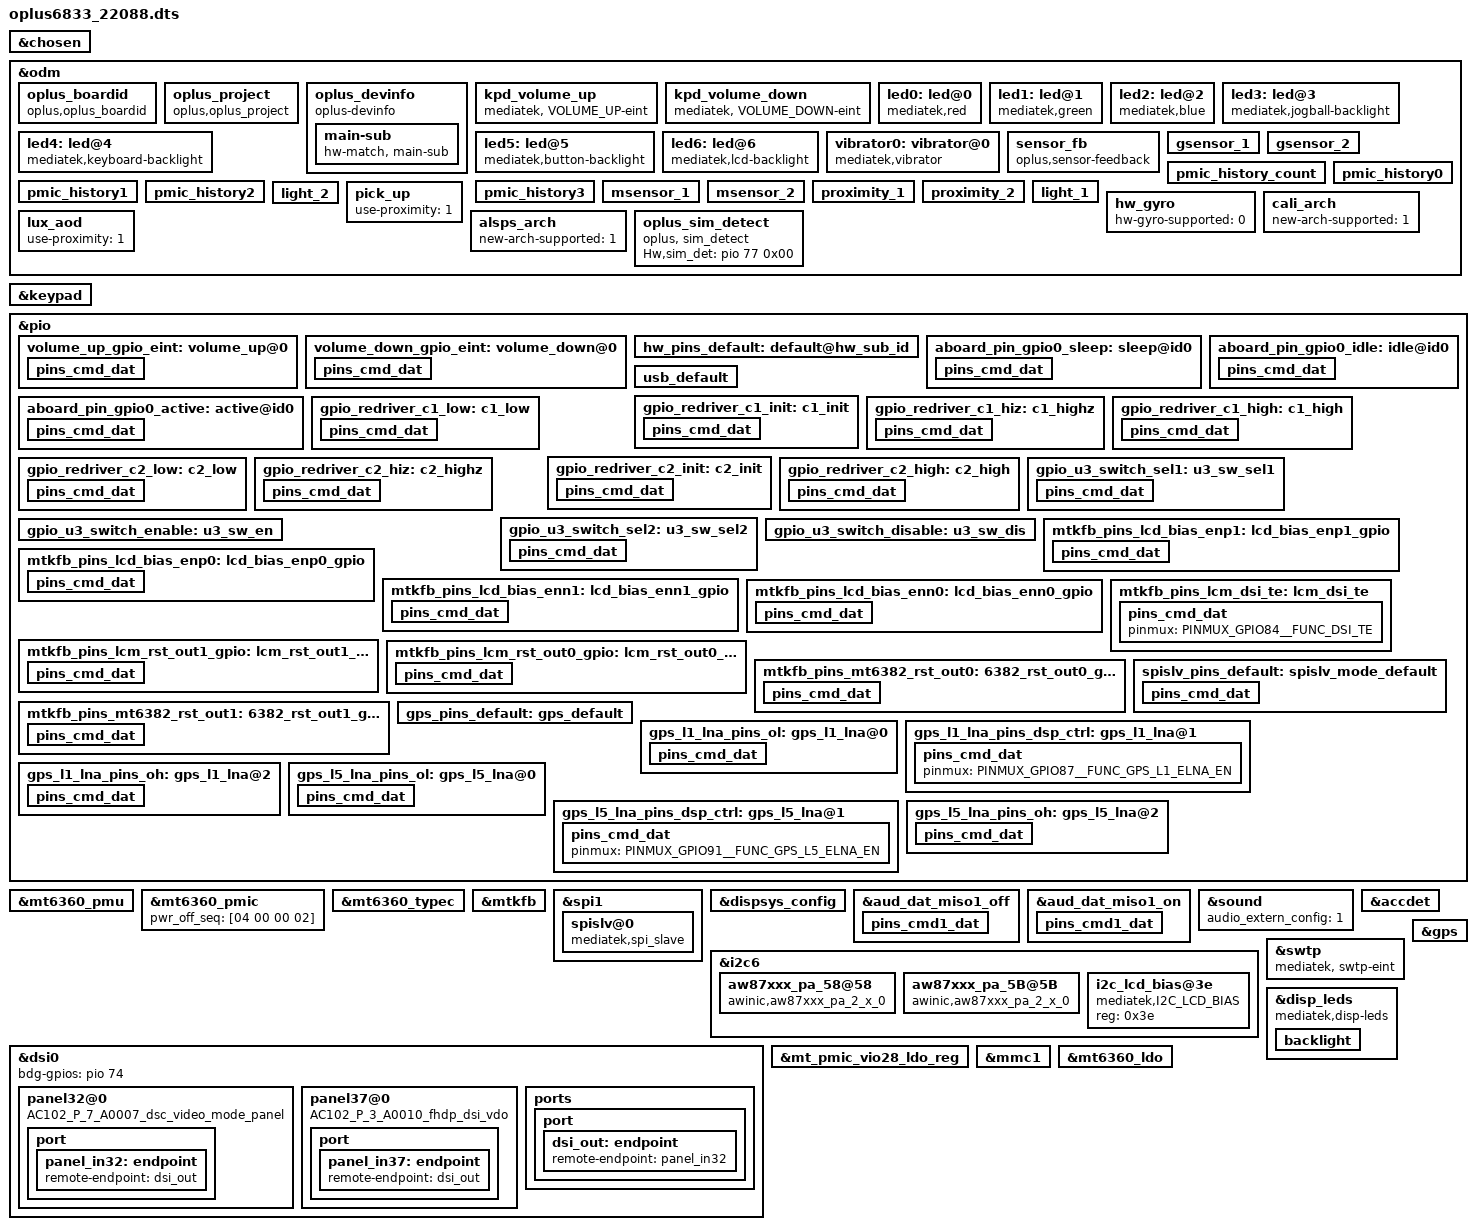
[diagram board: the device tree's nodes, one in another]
// SPDX-License-Identifier: GPL-2.0
/*
 * Copyright (c) 2019 MediaTek Inc.
 *
 */
/dts-v1/;
/plugin/;
#include <dt-bindings/interrupt-controller/irq.h>
#include <dt-bindings/interrupt-controller/arm-gic.h>
#ifndef CONFIG_FPGA_EARLY_PORTING
#include <dt-bindings/pinctrl/mt6833-pinfunc.h>
#endif

/* #ifdef CONFIG_UFF_FINGERPRINT */
#include "mediatek/oplus_uff_22087.dtsi"
/* #endif CONFIG_UFF_FINGERPRINT */

/* chosen */
&chosen {
	atag,videolfb-fb_base_l = <0x7e605000>;
	atag,videolfb-fb_base_h = <0x0>;
	atag,videolfb-islcmfound = <1>;
	atag,videolfb-islcm_inited = <0>;
	atag,videolfb-fps= <6000>;
	atag,videolfb-vramSize= <0x1be0000>;
	atag,videolfb-lcmname=
		"nt35595_fhd_dsi_cmd_truly_nt50358_drv";
};

&odm {
	oplus_boardid:oplus_boardid {
		compatible = "oplus,oplus_boardid";
		oplus_boardid,dtsino="22088";//only one u32
		oplus_boardid,pcbmask="0xffff";//all mask 0xffff
	};
	oplus_project:oplus_project {
		compatible = "oplus,oplus_project";
	};

	oplus_devinfo:oplus_devinfo {
		compatible = "oplus-devinfo";
		pinctrl-names = "default", "aboard_gpio0_sleep", "aboard_gpio0_active", "aboard_gpio0_idle";
		pinctrl-0 = <&hw_pins_default>;
		pinctrl-1 = <&aboard_pin_gpio0_sleep>;
		pinctrl-2 = <&aboard_pin_gpio0_active>;
		pinctrl-3 = <&aboard_pin_gpio0_idle>;
		main-sub {
			use_tristate_gpio;
			compatible = "hw-match, main-sub";
			aboard-gpio0 = <&pio 19 0x00>;
			aboard-patterns = <1>;	/*0[high-resistance] 1[pull-down] 2[pull-up]*/
			/*main board*/
			match-projects = <22088>;
		};
	};

	kpd_volume_up:kpd_volume_up {
		compatible = "mediatek, VOLUME_UP-eint";
		interrupt-parent = <&pio>;
		interrupts = <1 IRQ_TYPE_EDGE_FALLING 1 0>;
		debounce = <32000>;
		status = "okay";
	};

	kpd_volume_down:kpd_volume_down {
		compatible = "mediatek, VOLUME_DOWN-eint";
		interrupt-parent = <&pio>;
		interrupts = <80 IRQ_TYPE_EDGE_FALLING 80 0>;
		debounce = <32000>;
		status = "okay";
	};
};
&keypad {
	keypad,volume-up	= <&pio 1 0x00>;
	keypad,volume-down	= <&pio 80 0x00>;
	pinctrl-names = "volume_up_as_int", "volume_down_as_int";
	pinctrl-0 = <&volume_up_gpio_eint>;
	pinctrl-1 = <&volume_down_gpio_eint>;
	status = "okay";
};
&pio {
	volume_up_gpio_eint:volume_up@0{
		pins_cmd_dat {
			pinmux = <PINMUX_GPIO1__FUNC_GPIO1>;
			slew-rate = <0>;  /*direction 0:in, 1:out*/
			input-enable;
		};
	};

	volume_down_gpio_eint:volume_down@0{
		pins_cmd_dat {
			pinmux = <PINMUX_GPIO80__FUNC_GPIO80>;
			slew-rate = <0>;  /*direction 0:in, 1:out*/
			input-enable;
		};
	};

	hw_pins_default:default@hw_sub_id {
	};
	aboard_pin_gpio0_sleep:sleep@id0 {
		pins_cmd_dat {
			pinmux = <PINMUX_GPIO19__FUNC_GPIO19>;
			slew-rate = <0>;
			bias-pull-down;
			input-enable;
		};
	};

	aboard_pin_gpio0_active:active@id0 {
		pins_cmd_dat {
			pinmux = <PINMUX_GPIO19__FUNC_GPIO19>;
			slew-rate = <0>;
			bias-pull-up;
			input-enable;
		};
	};

	aboard_pin_gpio0_idle:idle@id0 {
		pins_cmd_dat {
			pinmux = <PINMUX_GPIO19__FUNC_GPIO19>;
			slew-rate = <0>;
			bias-disable;
			input-enable;
		};
	};
};

/* USB SWITCH GPIO start */
&pio {
	usb_default: usb_default {
	};

	gpio_redriver_c1_init: c1_init {
		pins_cmd_dat {
			pinmux = <PINMUX_GPIO41__FUNC_GPIO41>;
			slew-rate = <1>;
			output-low;
		};
	};

	gpio_redriver_c1_low: c1_low {
		pins_cmd_dat {
			pinmux = <PINMUX_GPIO41__FUNC_GPIO41>;
			slew-rate = <1>;
			output-low;
		};
	};

	gpio_redriver_c1_hiz: c1_highz {
		pins_cmd_dat {
			pinmux = <PINMUX_GPIO41__FUNC_GPIO41>;
			slew-rate= <0>;
			bias-disable;
		};
	};

	gpio_redriver_c1_high: c1_high {
		pins_cmd_dat {
			pinmux = <PINMUX_GPIO41__FUNC_GPIO41>;
			slew-rate = <1>;
			output-high;
		};
	};

	gpio_redriver_c2_init: c2_init {
		pins_cmd_dat {
			pinmux = <PINMUX_GPIO40__FUNC_GPIO40>;
			slew-rate = <1>;
			output-low;
		};
	};

	gpio_redriver_c2_low: c2_low {
		pins_cmd_dat {
			pinmux = <PINMUX_GPIO40__FUNC_GPIO40>;
			slew-rate = <1>;
			output-low;
		};
	};

	gpio_redriver_c2_hiz: c2_highz {
		pins_cmd_dat {
			pinmux = <PINMUX_GPIO40__FUNC_GPIO40>;
			slew-rate= <0>;
			bias-disable;
		};
	};

	gpio_redriver_c2_high: c2_high {
		pins_cmd_dat {
			pinmux = <PINMUX_GPIO40__FUNC_GPIO40>;
			slew-rate = <1>;
			output-high;
		};
	};

	gpio_u3_switch_sel1: u3_sw_sel1 {
		pins_cmd_dat {
			pinmux = <PINMUX_GPIO11__FUNC_GPIO11>;
			slew-rate = <1>;
			output-low;
		};
	};

	gpio_u3_switch_sel2: u3_sw_sel2 {
		pins_cmd_dat {
			pinmux = <PINMUX_GPIO11__FUNC_GPIO11>;
			slew-rate = <1>;
			output-high;
		};
	};

	gpio_u3_switch_enable: u3_sw_en {
	};

	gpio_u3_switch_disable: u3_sw_dis {
	};
};

&mt6360_pmu {
	mt6360,intr_gpio_num = <10>; /* direct defined GPIO num */
	mt6360,intr_gpio = <&pio 10 0x0>;
};

&mt6360_pmic {
	pwr_off_seq = [04 00 00 02];
};

&mt6360_typec {
	mt6360pd,intr_gpio_num = <9>; /* direct defined GPIO num */
	mt6360pd,intr_gpio = <&pio 9 0x0>;
};

#ifndef CONFIG_FPGA_EARLY_PORTING
&pio {
	mtkfb_pins_lcd_bias_enp1: lcd_bias_enp1_gpio {
		pins_cmd_dat {
			pinmux = <PINMUX_GPIO137__FUNC_GPIO137>;
			slew-rate = <1>;
			output-high;
		};
	};

	mtkfb_pins_lcd_bias_enp0: lcd_bias_enp0_gpio {
		pins_cmd_dat {
			pinmux = <PINMUX_GPIO137__FUNC_GPIO137>;
			slew-rate = <1>;
			output-low;
		};
	};

	mtkfb_pins_lcd_bias_enn1: lcd_bias_enn1_gpio {
		pins_cmd_dat {
			pinmux = <PINMUX_GPIO138__FUNC_GPIO138>;
			slew-rate = <1>;
			output-high;
		};
	};

	mtkfb_pins_lcd_bias_enn0: lcd_bias_enn0_gpio {
		pins_cmd_dat {
			pinmux = <PINMUX_GPIO138__FUNC_GPIO138>;
			slew-rate = <1>;
			output-low;
		};
	};

	mtkfb_pins_lcm_rst_out1_gpio: lcm_rst_out1_gpio {
		pins_cmd_dat {
			pinmux = <PINMUX_GPIO86__FUNC_GPIO86>;
			slew-rate = <1>;
			output-high;
		};
	};

	mtkfb_pins_lcm_rst_out0_gpio: lcm_rst_out0_gpio {
		pins_cmd_dat {
			pinmux = <PINMUX_GPIO86__FUNC_GPIO86>;
			slew-rate = <1>;
			output-low;
		};
	};
	mtkfb_pins_lcm_dsi_te: lcm_dsi_te {
		pins_cmd_dat {
			pinmux = <PINMUX_GPIO84__FUNC_DSI_TE>;
		};
	};

	mtkfb_pins_mt6382_rst_out0: 6382_rst_out0_gpio {
                pins_cmd_dat {
                        pinmux = <PINMUX_GPIO74__FUNC_GPIO74>;
                        slew-rate = <1>;
                        output-low;
                };
        };
	mtkfb_pins_mt6382_rst_out1: 6382_rst_out1_gpio {
                pins_cmd_dat {
                        pinmux = <PINMUX_GPIO74__FUNC_GPIO74>;
                        slew-rate = <1>;
                        output-high;
                };
        };
};

&mtkfb {
	pinctrl-names = "lcd_bias_enp1_gpio", "lcd_bias_enp0_gpio",
		"lcd_bias_enn1_gpio", "lcd_bias_enn0_gpio",
		"lcm_rst_out1_gpio", "lcm_rst_out0_gpio",
		"mode_te_te","6382_rst_out0_gpio","6382_rst_out1_gpio";
	pinctrl-0 = <&mtkfb_pins_lcd_bias_enp1>;
	pinctrl-1 = <&mtkfb_pins_lcd_bias_enp0>;
	pinctrl-2 = <&mtkfb_pins_lcd_bias_enn1>;
	pinctrl-3 = <&mtkfb_pins_lcd_bias_enn0>;
	pinctrl-4 = <&mtkfb_pins_lcm_rst_out1_gpio>;
	pinctrl-5 = <&mtkfb_pins_lcm_rst_out0_gpio>;
	pinctrl-6 = <&mtkfb_pins_lcm_dsi_te>;
	pinctrl-7 = <&mtkfb_pins_mt6382_rst_out0>;
	pinctrl-8 = <&mtkfb_pins_mt6382_rst_out1>;
	status = "okay";
	oplus_display_mt6382_support;
};
&spi1 {
	status = "okay";
	#address-cells = <1>;
	#size-cells = <0>;
	pinctrl-names = "default";
	pinctrl-0 = <&spislv_pins_default>;
	mediatek,fifo-polling = <1>;
	mediatek,kthread-rt = <1>;

	spislv@0 {
		compatible = "mediatek,spi_slave";
		reg = <0>;
		spi-max-frequency = <55000000>;
		spi-tx-bus-width = <1>;
		spi-rx-bus-width = <1>;
		low-speed-tick-delay = /bits/ 8 <4>;
		low-speed-early-trans = /bits/ 8 <0>;
		high-speed-tick-delay = /bits/ 8 <1>;
		high-speed-early-trans = /bits/ 8 <0>;
		slave-drive-strength = /bits/ 8 <3>;
	};
};
&pio {
	spislv_pins_default: spislv_mode_default {
		pins_cmd_dat {
			pinmux = <PINMUX_GPIO30__FUNC_SPI1_MI>,
					<PINMUX_GPIO28__FUNC_SPI1_CSB>,
					<PINMUX_GPIO29__FUNC_SPI1_MO>,
					<PINMUX_GPIO27__FUNC_SPI1_CLK>;
					 drive-strength = <3>;
				};
	};
};
&dispsys_config {
	pinctrl-names =
		"lcm_rst_out1_gpio", "lcm_rst_out0_gpio",
		"mode_te_te","6382_rst_out0_gpio", "6382_rst_out1_gpio";
	pinctrl-0 = <&mtkfb_pins_lcm_rst_out1_gpio>;
	pinctrl-1 = <&mtkfb_pins_lcm_rst_out0_gpio>;
	pinctrl-2 = <&mtkfb_pins_lcm_dsi_te>;
	pinctrl-3 = <&mtkfb_pins_mt6382_rst_out0>;
	pinctrl-4 = <&mtkfb_pins_mt6382_rst_out1>;
	status = "okay";

	helper-value = <0>, /*MTK_DRM_OPT_STAGE*/
		<1>, /*MTK_DRM_OPT_USE_CMDQ*/
		<1>, /*MTK_DRM_OPT_USE_M4U*/
		<0>, /*MTK_DRM_OPT_SODI_SUPPORT*/
		<1>, /*MTK_DRM_OPT_IDLE_MGR*/
		<0>, /*MTK_DRM_OPT_IDLEMGR_SWTCH_DECOUPLE*/
		<0>, /*MTK_DRM_OPT_IDLEMGR_BY_REPAINT*/
		<0>, /*MTK_DRM_OPT_IDLEMGR_ENTER_ULPS*/
		<0>, /*MTK_DRM_OPT_IDLEMGR_KEEP_LP11*/
		<0>, /*MTK_DRM_OPT_DYNAMIC_RDMA_GOLDEN_SETTING*/
		<1>, /*MTK_DRM_OPT_IDLEMGR_DISABLE_ROUTINE_IRQ*/
		<0>, /*MTK_DRM_OPT_MET_LOG*/
		<1>, /*MTK_DRM_OPT_USE_PQ*/
		<1>, /*MTK_DRM_OPT_ESD_CHECK_RECOVERY*/
		<1>, /*MTK_DRM_OPT_ESD_CHECK_SWITCH*/
		<1>, /*MTK_DRM_OPT_PRESENT_FENCE*/
		<0>, /*MTK_DRM_OPT_RDMA_UNDERFLOW_AEE*/
		<1>, /*MTK_DRM_OPT_DSI_UNDERRUN_AEE*/
		<1>, /*MTK_DRM_OPT_HRT*/
		<1>, /*MTK_DRM_OPT_HRT_MODE*/
		<0>, /*MTK_DRM_OPT_DELAYED_TRIGGER*/
		<1>, /*MTK_DRM_OPT_OVL_EXT_LAYER*/
		<0>, /*MTK_DRM_OPT_AOD*/
		<1>, /*MTK_DRM_OPT_RPO*/
		<0>, /*MTK_DRM_OPT_DUAL_PIPE*/
		<0>, /*MTK_DRM_OPT_DC_BY_HRT*/
		<0>, /*MTK_DRM_OPT_OVL_WCG*/
		<0>, /*MTK_DRM_OPT_OVL_SBCH*/
		<1>, /*MTK_DRM_OPT_COMMIT_NO_WAIT_VBLANK*/
		<0>, /*MTK_DRM_OPT_MET*/
		<0>, /*MTK_DRM_OPT_REG_PARSER_RAW_DUMP*/
		<0>, /*MTK_DRM_OPT_VP_PQ*/
		<0>, /*MTK_DRM_OPT_GAME_PQ*/
		<0>, /*MTK_DRM_OPT_MMPATH*/
		<1>, /*MTK_DRM_OPT_HBM*/
		<1>, /*MTK_DRM_OPT_VDS_PATH_SWITCH*/
		<0>, /*MTK_DRM_OPT_LAYER_REC*/
		<1>; /*MTK_DRM_OPT_CLEAR_LAYER*/
};

/* add for dual-mic or singlemic with miso1 */
&aud_dat_miso1_off {
	pins_cmd1_dat {
		pinmux = <PINMUX_GPIO160__FUNC_GPIO160>;
		input-enable;
		bias-pull-down;
	};
};
&aud_dat_miso1_on {
	pins_cmd1_dat {
		pinmux = <PINMUX_GPIO160__FUNC_AUD_DAT_MISO1>;
		input-schmitt-enable;
		bias-disable;
	};
};

&pio {

};

&sound {
	/* this dtsi config for product's special config, AudioHal read ctl 'OPLUS_AUDIO_EXTEN_CONFIG' get the values*
	 * 1st value --> PA type: 0:NXP Pa, 1:Awinic Pa 2:sia81xx Pa*/
	audio_extern_config = <1>;
};

&i2c6 {
	aw87xxx_pa_58@58 {
		compatible = "awinic,aw87xxx_pa_2_x_0";
		reset-gpio = <&pio 139 0>;
		reg = <0x58>;
		dev_index = < 1 >;
		status = "okay";
	};

	aw87xxx_pa_5B@5B {
		compatible = "awinic,aw87xxx_pa_2_x_0";
		reset-gpio = <&pio 131 0>;
		reg = <0x5B>;
		dev_index = < 0 >;
		status = "okay";
	};

       i2c_lcd_bias@3e {
               compatible = "mediatek,I2C_LCD_BIAS";
               reg = <0x3e>;
               status = "okay";
       };
};

&dsi0 {
	status = "okay";
	#address-cells = <1>;
	#size-cells = <0>;
	bdg-gpios = <&pio 74 0>;
	panel32@0 {
		compatible = "AC102_P_7_A0007_dsc_video_mode_panel";
		reg = <0>;
		reset-gpios = <&pio 86 0>;
        bias-gpios = <&pio 136 0>,
					 <&pio 137 0>,
                     <&pio 138 0>;
		pinctrl-names = "default";
		port {
			panel_in32: endpoint {
				remote-endpoint = <&dsi_out>;
			};
		};
	};
	panel37@0 {
		compatible = "AC102_P_3_A0010_fhdp_dsi_vdo";
		reg = <1>;
		reset-gpios = <&pio 86 0>;
		bias-gpios = <&pio 136 0>,
                     <&pio 137 0>,
                     <&pio 138 0>;
		pinctrl-names = "default";
		port {
			panel_in37: endpoint {
				remote-endpoint = <&dsi_out>;
			};
		};
	};
	ports {
		port {
			dsi_out: endpoint {
				remote-endpoint = <&panel_in32>;
			};
		};
	};
};
#endif

/* delete default keys pinctrl
&keypad {
	pinctrl-names = "default";
	pinctrl-0 = <&kpd_pins_default>;
};

&pio {
	kpd_pins_default: kpdgpiodefault {
		pins_cmd_dat {
			pinmux = <PINMUX_GPIO79__FUNC_KPCOL0>;
			bias-pull-up = <MTK_PUPD_SET_R1R0_10>;
			output-low;
			input-schmitt-enable;
		};
	};
};
*/

/* accdet start */
&accdet {
	/* accdet micbias voltage: 0x09:2.85v 0x08:2.8v 0x07,
	 * 2.7v;0x05,2.5v;0x02,1.9v
	 */
	accdet-mic-vol = <7>;
	/* accdet pwm_width, pwm_thresh, fall_delay, rise_delay
	 * debounce0, debounce1, debounce3, debounce4
	 * eint pwm_width, eint pwm_thresh
	 * eint deb(debounce0, debounce1, debounce2, debounce3), inv_debounce
	 */

	headset-mode-setting = <0x500 0x500 1 0x1f0
				0x1325 0x800 0x3D4 0x44
				0x0 0x7
				0x5 0x9 0x9 0xd 0xe>;
	/*headset-mode-setting = <0x500 0x500 1 0x1f0
	*                      0x800 0x800 0x20 0x44
	*                      0x4 0x1
	*                      0x5 0x3 0x3 0x5 0xe>;
	*/

	accdet-plugout-debounce = <1>;
	/*1:ACC mode, 2:low cost without in bias, 6:low cost with in bias*/
	accdet-mic-mode = <2>;
	/*0--MD_MAX--UP_MAX--DW_MAX*/
	headset-three-key-threshold = <0 82 170 306>;
	//headset-three-key-threshold = <0 80 220 400>;
	headset-three-key-threshold-CDD = <0 121 192 600>;
	/*0--MD_MAX--VOICE_MAX--UP_MAX--DW_MAX*/
	headset-four-key-threshold = <0 58 121 192 400>;
	/* moisture HW mode config start. Enable moisture detection or not
	 * default use HW mode for moisture detection
	 */
	moisture_detect_enable = <1>;
	/* select VTH to 2v and 500k, use internal resitance */
	eint_use_ext_res = <0>;
	/* enable eint detection mode, if moisture detection enable
	 * eint_detect_mode = moisture_detect_mode;otherwise, select
	 * eint_detect_mode = 4 as DEFAULT
	 */
	eint_detect_mode = <5>;
	/* enable moisture detection mode, if moisture detection enable
	 * eint_detect_mode = moisture_detect_mode
	 */
	moisture_detect_mode = <5>;
	/* select 0: 2.8V; 1: 2.4V; 2: 2V; 3: VTH=MVTH(VTH2) */
	moisture_comp_vth = <2>;
//#ifdef OPLUS_BUG_COMPATIBILITY
	moisture_comp_vref2 = <2>;
//#else
	/* vref2 voltage for different water impedance */
	//moisture_comp_vref2 = <0>;
//#endif
	/* moisture HW mode config end */

	/* moisture SW mode config start, use external resister or not.
	 * DEFAULT NOT NEED
	 */
	moisture_use_ext_res = <0>;
	/* moisture external resister ohm, SW mode by auxadc */
	moisture-external-r = <2000000>;
	/* moisture internal resister ohm, SW mode by auxadc */
	moisture-internal-r = <47000>;
	/* moisture of water resister ohm, SW mode by auxadc*/
	moisture-water-r = <10000>;
	/* moisture SW mode config end */
        //#endif /* VENDOR_EDIT */
	status = "okay";
};
/* accdet end */

//#ifdef OPLUS_FEATURE_SWTP
&swtp {
    compatible = "mediatek, swtp-eint";
};
//#endif  /*OPLUS_FEATURE_SWTP*/

&disp_leds {
	compatible = "mediatek,disp-leds";
        backlight {
                label = "lcd-backlight";
                led_mode = <4>;
                max-brightness = <4095>;
                max-hw-brightness = <4095>;
                led-bits = <12>;
                trans-bits = <12>;
                default-state = "on";
        };
};

&mt_pmic_vio28_ldo_reg {
	regulator-name = "vio28";
	regulator-min-microvolt = <3300000>;
	regulator-max-microvolt = <3300000>;
	regulator-enable-ramp-delay = <1920>;
};

&odm {
	led0:led@0 {
		compatible = "mediatek,red";
		led_mode = <0>;
		data = <1>;
		pwm_config = <0 0 0 0 0>;
	};
	led1:led@1 {
		compatible = "mediatek,green";
		led_mode = <0>;
		data = <1>;
		pwm_config = <0 0 0 0 0>;
	};
	led2:led@2 {
		compatible = "mediatek,blue";
		led_mode = <0>;
		data = <1>;
		pwm_config = <0 0 0 0 0>;
	};
	led3:led@3 {
		compatible = "mediatek,jogball-backlight";
		led_mode = <0>;
		data = <1>;
		pwm_config = <0 0 0 0 0>;
	};
	led4:led@4 {
		compatible = "mediatek,keyboard-backlight";
		led_mode = <0>;
		data = <1>;
		pwm_config = <0 0 0 0 0>;
	};
	led5:led@5 {
		compatible = "mediatek,button-backlight";
		led_mode = <0>;
		data = <1>;
		pwm_config = <0 0 0 0 0>;
	};
	led6:led@6 {
		compatible = "mediatek,lcd-backlight";
		led_mode = <4>;
		data = <1>;
		pwm_config = <0 1 0 0 0>;
	};
	vibrator0:vibrator@0 {
		compatible = "mediatek,vibrator";
	};
	sensor_fb: sensor_fb {
		compatible = "oplus,sensor-feedback";
	};

	/*
	enum {
		LIS3DH,
		LSM6DS3,
		BMI160,
		LIS2HH12,
		LSM6DSM,
		BMI2XY,
		LSM6DSO,
		ICM4X6XX,
		SC7A20,
		BMA4XY,
		BMI3XY,
		ICM4N607,
		BMA2X2,
		MC34X9,
		STK8XXX,
	};
	*/

	gsensor_1: gsensor_1 {
		status = "okay";
		sensor_name = <8>;//SC7A20
		device_name = "sc7a20";
		i2c_num = <2>;
		i2c_addr = <0>;
		direction = <6>;
		eint_num = <3>;
		gyro_cali_version= <2>;
		acc_cali_range= <300 300 300>; //300mg
		device_id = <0>; //0 sc7a20,1 sc7a20e
	};
	gsensor_2: gsensor_2 {
		status = "okay";
		sensor_name = <9>;//BMA4XY
		device_name = "bma4xy";
		i2c_num = <2>;
		i2c_addr = <0>;
		direction = <11>;
		eint_num = <3>;
		gyro_cali_version= <2>;
		acc_cali_range= <300 300 300>; //300mg
	};
	/*
	enum {
		AKM09911,
		MMC3530,
		MMC5603,
		MXG4300,
		QMC6308,
	};
	*/

	pmic_history_count:pmic_history_count {
	};
	pmic_history0:pmic_history0 {
	};
	pmic_history1:pmic_history1 {
	};
	pmic_history2:pmic_history2 {
	};
	pmic_history3:pmic_history3 {
	};

	msensor_1: msensor_1 {
		status = "okay";
		sensor_name = <2>;//MMC5603
		i2c_num = <0>;
		i2c_addr = <0x30>;
		direction = <1>;
		eint_num = <0>;
		soft-mag-parameter = <9992 0 234 1 249 1 173 0 9621 0 77 1 350 1 6 0 10277 0>;
	};
	msensor_2: msensor_2 {
		status = "okay";
		sensor_name = <3>;//MXG4300
		i2c_num = <0>;
		i2c_addr = <0x0C>;
		direction = <1>;
		eint_num = <0>;
		soft-mag-parameter = <10096 0 80 0 162 1 133 1 9521 0 109 0 66 1 76 1 10386 0>;
	};

	/*
	enum {
		TMD2725,
		APSD9922,
		STK3335,
		STK3331,
		STK2232,
		TCS3701,
		STK32600,
		STK33502,
		MN78911,
		TMD2755x12,
	};
	*/
	proximity_1: proximity_1 {
		status = "okay";
		sensor_name = <10>;//STK33C01
		i2c_num = <0>;
		i2c_addr = <0x48>;
		direction = <4>;
		eint_num = <2>;
		low_step = <300>;
		high_step = <400>;
		low_limit = <650>;
		high_limit = <1050>;
		dirty_low_step = <300>;
		dirty_high_step = <400>;
		ps_dirty_limit = <1800>;
		ps_ir_limit = <2000>;
		ps_adjust_min = <0>;
		ps_adjust_max = <1850>;
		sampling_count = <5>;
		step_max = <400>;
		step_min = <100>;
		step_div = <2000>;
		anti_shake_delta = <70>;
		dynamic_cali_max = <2000>;
		raw2offset_radio = <1000>;
		offset_max = <60000>;
		offset_range_min = <0>;
		offset_range_max = <65534>;
		force_cali_limit = <2000>;
		cali_jitter_limit = <30>;
		cal_offset_margin = <3000>;
		is_use_force_cali = <1>;
		parameter-number = <8>;
                sensor-reg = <0x01 0x43
				0x03 0x3C
				0x4E 0x60
				0xDB 0x00>; //override special reg
		/*sensor-reg end*/
	};
        proximity_2: proximity_2 {
		status = "okay";
		sensor_name = <11>; //SIP3535
		i2c_num = <0>;
		i2c_addr = <0x59>;
		direction = <4>;
		eint_num = <2>;
		low_step = <300>;
		high_step = <400>;
		low_limit = <650>;
		high_limit = <1050>;
		dirty_low_step = <300>;
		dirty_high_step = <400>;
		ps_dirty_limit = <1800>;
		ps_ir_limit = <2000>;
		ps_adjust_min = <0>;
		ps_adjust_max = <1850>;
		sampling_count = <5>;
		step_max = <400>;
		step_min = <100>;
		step_div = <2000>;
		anti_shake_delta = <70>;
		dynamic_cali_max = <2000>;
		raw2offset_radio = <1000>;
		offset_max = <60000>;
		offset_range_min = <0>;
		offset_range_max = <65534>;
		force_cali_limit = <2000>;
		cali_jitter_limit = <20>;
		cal_offset_margin = <3000>;
	};
	light_1: light_1 {
		status = "okay";
		sensor_name = <10>;//STK33C01
		i2c_num = <0>;
		i2c_addr = <0x48>;
		direction = <4>;
		eint_num = <2>;
		als_ratio = <210>;
		als_buffer_length =<8>;
		als_type = <1>;//<1-normal;2-under screen;3-normal needed compensation>
		device_name = "stk33c01";
		coefficient_mode = <6>;
		als_coef_a = <5670>; //*100
		als_coef_b = <5130>; //*100
		als_coef_c = <1820>; //*100
		als_coef_d = <1480>; //*100
		als_coef_e = <2780>; //*100
		als_coef_ratio = <600>;
	};
        light_2: light_2 {
		status = "okay";
		sensor_name = <11>; //SIP3535
		i2c_num = <0>;
		i2c_addr = <0x59>;
		direction = <4>;
		eint_num = <2>;
		als_ratio = <210>;
		als_buffer_length =<8>;
		als_type = <1>;//<1-normal;2-under screen;3-normal needed compensation>
		device_name = "sip3535";
		coefficient_mode = <6>;
		als_coef_a = <963>; //*100
		als_coef_b = <60>; //*100
		als_coef_c = <963>; //*100
		als_coef_d = <60>; //*100
		als_coef_e = <2490>; //*100
		als_coef_ratio = <1500>;
	};
	hw_gyro: hw_gyro {
		status = "okay";
		hw-gyro-supported = <0>;
	};
	cali_arch: cali_arch {
		status = "okay";
		new-arch-supported = <1>;
	};
	pick_up: pick_up {
		status = "okay";
		use-proximity = <1>;
	};
	lux_aod: lux_aod {
		status = "okay";
		use-proximity = <1>;
	};
	alsps_arch: alsps_arch {
		status = "okay";
		new-arch-supported = <1>;
	};
    oplus_sim_detect {
        compatible = "oplus, sim_detect";
        Hw,sim_det = <&pio 77 0x00>;
    };
};

/* GPS GPIO standardization start */
&pio {
	gps_pins_default: gps_default {
	};

	gps_l1_lna_pins_ol: gps_l1_lna@0 {
		pins_cmd_dat {
			pinmux = <PINMUX_GPIO87__FUNC_GPIO87>;
			output-low;
		};
	};
	gps_l1_lna_pins_dsp_ctrl: gps_l1_lna@1 {
		pins_cmd_dat {
			pinmux = <PINMUX_GPIO87__FUNC_GPS_L1_ELNA_EN>;
		};
	};
	gps_l1_lna_pins_oh: gps_l1_lna@2 {
		pins_cmd_dat {
			pinmux = <PINMUX_GPIO87__FUNC_GPIO87>;
			output-high;
		};
	};

	gps_l5_lna_pins_ol: gps_l5_lna@0 {
		pins_cmd_dat {
			pinmux = <PINMUX_GPIO91__FUNC_GPIO91>;
			output-low;
		};
	};
	gps_l5_lna_pins_dsp_ctrl: gps_l5_lna@1 {
		pins_cmd_dat {
			pinmux = <PINMUX_GPIO91__FUNC_GPS_L5_ELNA_EN>;
		};
	};
	gps_l5_lna_pins_oh: gps_l5_lna@2 {
		pins_cmd_dat {
			pinmux = <PINMUX_GPIO91__FUNC_GPIO91>;
			output-high;
		};
	};
};

&gps {
	pinctrl-names = "default",
		"gps_l1_lna_disable",
		"gps_l1_lna_dsp_ctrl",
		"gps_l1_lna_enable",
		"gps_l5_lna_disable",
		"gps_l5_lna_dsp_ctrl",
		"gps_l5_lna_enable";
	pinctrl-0 = <&gps_pins_default>;
	pinctrl-1 = <&gps_l1_lna_pins_ol>;
	pinctrl-2 = <&gps_l1_lna_pins_dsp_ctrl>;
	pinctrl-3 = <&gps_l1_lna_pins_oh>;
	pinctrl-4 = <&gps_l5_lna_pins_ol>;
	pinctrl-5 = <&gps_l5_lna_pins_dsp_ctrl>;
	pinctrl-6 = <&gps_l5_lna_pins_oh>;
	status = "okay";
};

/* GPS GPIO standardization end */
#include "mediatek/cust_mt6833_camera_22088.dtsi"
#include <oplus6833_22088/cust.dtsi>

/*Touch*/
#include "mediatek/cust_mt6833_touch_22087.dtsi"

//#ifdef OPLUS_FEATURE_CHG_BASIC
#include "mediatek/oplus_charge_mt6833_fanli_33W.dtsi"
//#endif
&mmc1 {
    cd-gpios = <&pio 4 0>;
    status = "okay";
    vmmc-supply = <&mt_pmic_vmch_ldo_reg>;
};
&mt6360_ldo {
	sdcard_det_en = <1>;
	sdcard_hlact = <0>;
};
/*End of this file, DO NOT ADD ANYTHING HERE*/
